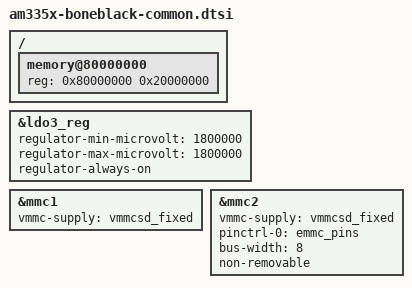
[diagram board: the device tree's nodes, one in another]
&ldo3_reg {
	regulator-min-microvolt = <1800000>;
	regulator-max-microvolt = <1800000>;
	regulator-always-on;
};
&mmc1 {
	vmmc-supply = <&vmmcsd_fixed>;
};
&mmc2 {
	vmmc-supply = <&vmmcsd_fixed>;
	pinctrl-names = "default";
	pinctrl-0 = <&emmc_pins>;
	bus-width = <8>;
	status = "okay";
	non-removable;
};
/ {
	memory@80000000 {
		device_type = "memory";
		reg = <0x80000000 0x20000000>;  
	};
};
